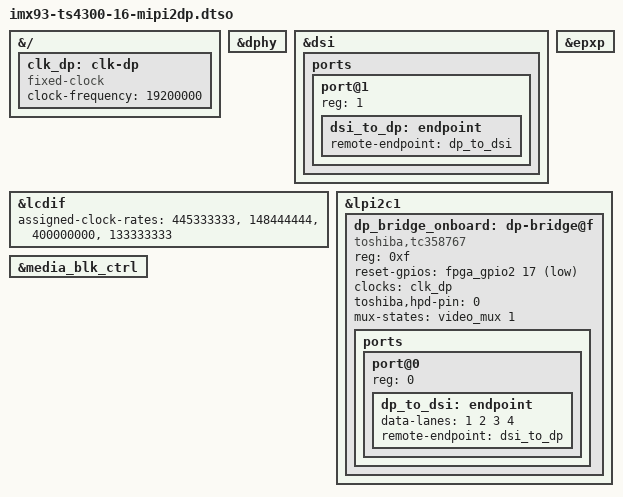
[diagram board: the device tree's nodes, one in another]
// SPDX-License-Identifier: GPL-2.0 OR X11
/*
 * Copyright 2024-2025 Technologic Systems, Inc. dba embeddedTS
 */

/dts-v1/;
/plugin/;
#include <dt-bindings/gpio/gpio.h>

&{/} {
	clk_dp: clk-dp {
		compatible = "fixed-clock";
		#clock-cells = <0>;
		clock-frequency = <19200000>;
	};
};

&dphy {
	status = "okay";
};

&dsi {
	status = "okay";

	ports {
		#address-cells = <1>;
		#size-cells = <0>;
		port@1 {
			reg = <1>;

			dsi_to_dp: endpoint {
				remote-endpoint = <&dp_to_dsi>;
			};
		};
	};
};

&epxp {
	status = "okay";
};

&lcdif {
	status = "okay";
	assigned-clock-rates = <445333333>, <148444444>, <400000000>, <133333333>;
};

&lpi2c1 {
	status = "okay";
	#address-cells = <1>;
	#size-cells = <0>;

	dp_bridge_onboard: dp-bridge@f {
		compatible = "toshiba,tc358767"; 
		reg = <0xf>;
		reset-gpios = <&fpga_gpio2 17 GPIO_ACTIVE_LOW>;

		clock-names = "ref";
		clocks = <&clk_dp>;

		toshiba,hpd-pin = <0>;
		status = "okay";
		mux-states = <&video_mux 1>;

		ports {
			#address-cells = <1>;
			#size-cells = <0>;

			port@0 {
				reg = <0>;

				dp_to_dsi: endpoint {
					data-lanes = <1 2 3 4>;
					remote-endpoint = <&dsi_to_dp>;
				};
			};
		};
	};
};

&media_blk_ctrl {
	status = "okay";
};
